# NANO100AN_v1 register map
File version: 1.0
Registers are 32-bit, read-write, reset 0x0 unless marked. A register's access mark holds for its fields unless they carry their own. Offsets are from the block's base; [hi:lo] are bit positions.

## FMC — FMC Register Map
Base 0x5000C000
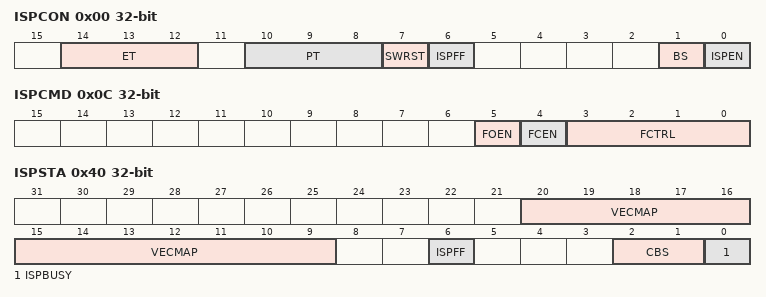
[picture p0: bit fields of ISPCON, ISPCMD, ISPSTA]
0x00 ISPCON — ISP Control Register
  [14:12] ET — Flash Erase Time (Write-Protection Bits)
  [10:8] PT — Flash Program Time (Write-Protection Bits)
  [7] SWRST — Software Reset. Writing 1 to this bit to start software reset. It is cleared by hardware after reset is finished.
  [6] ISPFF — ISP Fail Flag (Write-Protection Bit). This bit is set by hardware when a triggered ISP meets any of the following conditions: (1) APROM writes to itself (2) LDROM writes to itself (3) CONFIG is erased/programmed when the MCU is running in APROM (4) Destination address is illegal, such as over an available range. Write 1 to clear.
  [1] BS — Boot Select (Write-Protection Bit). Set/clear this bit to select next booting from LDROM/APROM, respectively. This bit also functions as chip booting status flag, which can be used to check where chip booted from. This bit is initiated with the inversed value of CBS in Config0 after power-on reset; It keeps the same value at other reset.
    0=boot from APROM; 1=boot from LDROM
  [0] ISPEN — ISP Enable (Erite-Protection Bit). ISP function enable bit. Set this bit to enable ISP function.
    0=ISP function Disabled; 1=ISP function Enabled
0x04 ISPADR — ISP Address Register
  [31:0] ISPADR — ISP Address. This chip supports word program only. ISPADR[1:0] must be kept 00b for ISP operation.
0x08 ISPDAT — ISP Data Register
  [31:0] ISPDAT — ISP Data. Write data to this register before ISP program operation. Read data from this register after ISP read operation.
0x0C ISPCMD — ISP Command Register
  [5] FOEN — ISP Command. The ISP command table is shown as follows.
  [4] FCEN — ISP Command. The ISP command table is shown as follows.
  [3:0] FCTRL — ISP Command
0x10 ISPTRG — ISP Trigger Control Register
  [0] ISPGO — ISP Start Trigger. Write 1 to start ISP operation and this bit will be cleared to 0 by hardware automatically when ISP operation is finished.
    0=ISP operation is finished; 1=ISP is on going
0x14 DFBADR ro reset 0x1F000 — Data Flash Base Address
  [31:0] DFBA — Data Flash Base Address. This register indicates data flash start address. It is a read only register. The data flash start address is defined by user. Since on chip flash erase unit is 512 bytes, it is mandatory to keep bit 8-0 as 0.
0x40 ISPSTA — ISP Status Register
  [20:9] VECMAP ro — Vector Page Mapping Address (Read Only). The current system memory space 0x0000_0000~0x0000_01FF is mapped to flash memory page with base address (VECMAP[11:0] 9). When chip is reset, the remapping address (VECMAP) is clear to CONFIG0 (CBS) default address setting.
  [6] ISPFF — ISP Fail Flag. This bit is set by hardware when a triggered ISP meets any of the following conditions: (1) APROM writes to itself. (2) LDROM writes to itself. (3) CONFIG is erased/programmed when the MCU is running in APROM. (4) Destination address is illegal, such as over an available range. Write 1 to clear.
  [2:1] CBS — Config Boot Selection Status
  [0] ISPBUSY — ISP BUSY . Read Only
    0=ISP operation is finished; 1=ISP operation is busy

## EBI — EBI Register Map
Base 0x50010000
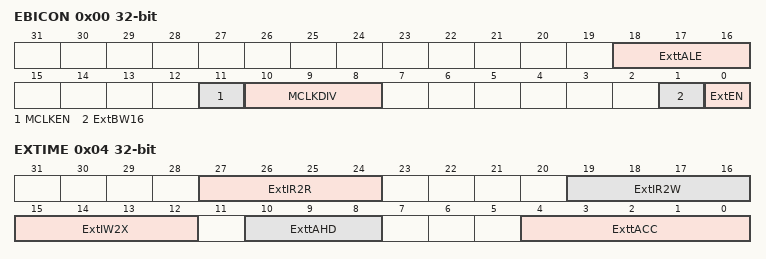
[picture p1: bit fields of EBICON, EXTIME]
0x00 EBICON — External Bus Interface General Control Register
  [18:16] ExttALE — Expand Time Of ALE. The ALE width (tALE) to latch the address can be controlled by ExttALE.
  [11] MCLKEN — External Clock Enable Control. This bit control if EBI generates the clock to external device. If external device is a synchronous device, it's necessary to set this bit high to enable EBI generating clock to external device.
    1=Enabled EBI to generate clock to external device
  [10:8] MCLKDIV — External Output Clock Divider. The frequency of EBI output clock is controlled by MCLKDIV as shown in the following table.
    0=HCLK/1; 1=HCLK/2; 2=HCLK/4; 3=HCLK/8; 4=HCLK/16; 5=HCLK/32; 6=HCLK/1; 7=HCLK/1
  [1] ExtBW16 — EBI Data Width 16-Bit. This bit defines if the data bus is 8-bit or 16-bit.
    0=EBI data width is 8-bit; 1=EBI data width is 16-bit
  [0] ExtEN — EBI Enable Control. This bit is the functional enable bit for EBI.
    0=EBI function is disabled; 1=EBI function is enabled
0x04 EXTIME — External Bus Interface Timing Control Register
  [27:24] ExtIR2R — Idle State Cycle Between Read-Read. When read action is finish and next action is going to read, idle state is inserted and nCS return to high if ExtIR2R is not zero.
  [19:16] ExtIR2W — Idle State Cycle Between Read-Write. When read action is finish and next action is going to write, idle state is inserted and nCS return to high if ExtIR2W is not zero.
  [15:12] ExtIW2X — Idle State Cycle After Write. When write action is finish, idle state is inserted and nCS return to high if ExtIW2X is not zero.
  [10:8] ExttAHD — EBI Data Access Hold Time. ExttAHD define data access hold time (tAHD).
  [4:0] ExttACC — EBI Data Access Time. ExttACC define data access time (tACC).
